VERSION ""

NS_ :

BS_:

BU_: PLEX

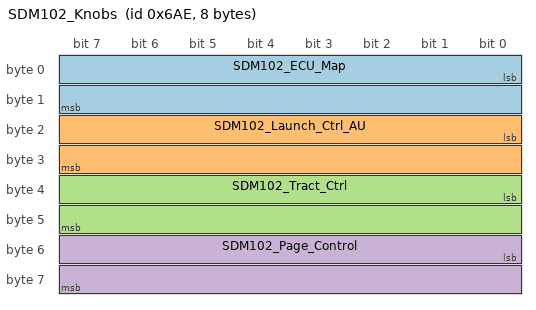
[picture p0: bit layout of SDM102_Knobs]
BO_ 1710 SDM102_Knobs: 8 PLEX
 SG_ SDM102_ECU_Map : 0|16@1- (1,0) [0|0] "" Vector__XXX
 SG_ SDM102_Launch_Ctrl_AU : 16|16@1- (1,0) [0|0] "" Vector__XXX
 SG_ SDM102_Tract_Ctrl : 32|16@1- (1,0) [0|0] "" Vector__XXX
 SG_ SDM102_Page_Control : 48|16@1- (1,0) [0|0] "" Vector__XXX
